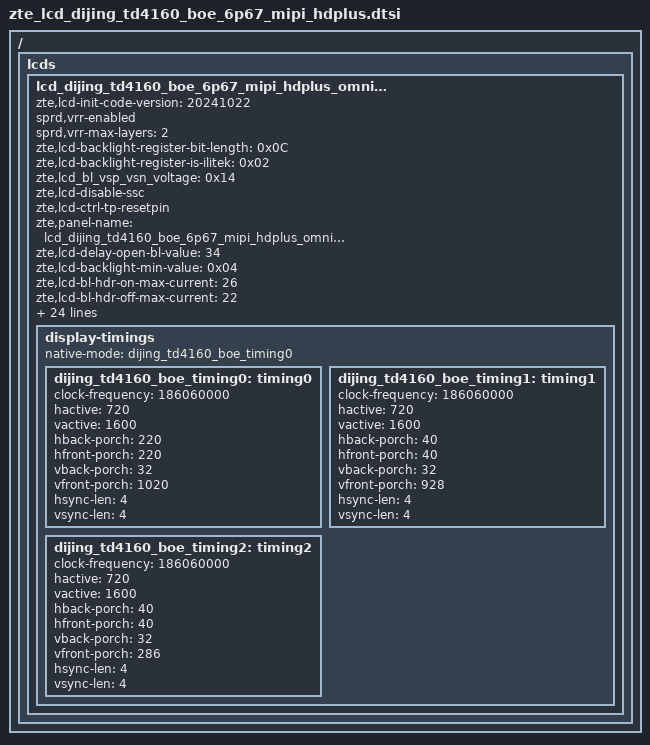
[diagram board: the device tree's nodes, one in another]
/ {
	fragment {
		target-path = "/";
		__overlay__ {
			lcds {
				lcd_dijing_td4160_boe_6p67_mipi_hdplus_omnivision: lcd_dijing_td4160_boe_6p67_mipi_hdplus_omnivision {
					zte,lcd-init-code-version = "20241022";
					sprd,vrr-enabled;
					sprd,vrr-max-layers = <2>;
					zte,lcd-backlight-register-bit-length = <0x0C>;
					zte,lcd-backlight-register-is-ilitek = <0x02>;/*51h=0xff0f*/
					zte,lcd_bl_vsp_vsn_voltage = <0x14>;
					zte,lcd-disable-ssc;
					zte,lcd-ctrl-tp-resetpin;
					zte,panel-name = "lcd_dijing_td4160_boe_6p67_mipi_hdplus_omnivision";
					zte,lcd-delay-open-bl-value = <34>;
					zte,lcd-backlight-min-value = <0x04>;
					zte,lcd-bl-hdr-on-max-current = <26>;
					zte,lcd-bl-hdr-off-max-current = <22>;

					sprd,dsi-work-mode = <1>;
					sprd,dsi-lane-number = <4>;
					sprd,dsi-color-format = "rgb888";

					sprd,dpi-clk-div = <6>;
					sprd,video-lp-cmd-enable = <1>;
					sprd,hporch-lp-disable = <1>;

					sprd,phy-bit-clock = <1116360>;
					sprd,phy-escape-clock = <20000>;/* kHz */

					sprd,width-mm = <6955>;
					sprd,height-mm = <15456>;

					sprd,esd-check-enable = <1>;/* 0:close , 1:open */
					sprd,esd-check-mode = <1>;/* 0:REG ,1:TE  */
					sprd,esd-check-period = <2000>;
					sprd,esd-check-register = <0x0A>;
					sprd,esd-check-value = <0x9C>;

					sprd,dphy-taget-val = <5>;

					sprd,reset-on-sequence = <1 5>, <0 15>, <1 50>;
					sprd,reset-off-sequence = <0 20>;

		sprd,initial-command = [
29 00 00 02 B0 00
29 00 00 07 B6 30 6b 00 86 c3 03
29 00 00 05 B7 31 00 00 00
29 00 00 07 B8 00 78 64 10 64 b4
29 00 00 07 B9 00 78 64 10 64 b4
29 00 00 07 BA 00 78 64 10 64 b4
29 00 00 04 BB 00 b4 a0
29 00 00 04 BC 00 b4 a0
29 00 00 04 BD 00 b4 a0
29 00 00 0E BE 07 00 00 00 00 00 00 00 00 00 00 00 00
29 00 00 19 C0 00 45 24 06 40 00 0a 06 94 00 70 00 00 00 00 00 00 00 00 00 00 00 00 00
29 00 00 28 C1 30 81 50 fa 01 00 00 10 00 00 00 00 40 0f 00 00 00 00 00 00 00 00 00 00 00 00 00 00 00 00 00 00 00 00 00 00 00 00 00
29 00 00 F5 C2 03 90 39 12 09 10 13 12 00 03 90 39 12 09 10 0f 11 00 00 00 00 00 00 00 00 00 00 00 00 00 00 00 00 00 00 00 00 00 00 00 00 00 03 90 32 10 10 08 05 c9 00 f0 01 00 00 00 08 00 00 00 00 11 00 f0 01 00 00 00 00 00 00 00 00 00 00 00 00 00 00 00 00 00 00 00 00 00 00 00 00 00 00 00 00 11 00 00 00 00 00 00 00 00 00 00 00 00 00 00 00 00 00 00 00 00 00 00 00 00 00 00 00 00 00 00 00 11 00 00 00 00 00 00 00 00 00 00 00 00 00 00 00 00 00 00 00 00 00 00 00 00 00 00 00 00 00 00 00 11 00 00 00 00 00 00 00 00 00 00 00 00 00 00 00 00 00 00 00 00 00 00 00 00 00 00 00 00 00 00 00 00 00 00 00 00 00 00 00 10 00 00 00 00 00 00 00 00 00 00 00 00 00 00 00 02 00 00 00 00 00 00 00 00 00 00 02 00 00 00 00 00 00 00 00 00 00 00 00 00 00 00 00 00 00 00
29 00 00 6A C3 03 90 39 c1 01 40 09 00 00 00 20 00 00 00 00 01 00 00 00 00 00 00 23 00 00 60 48 c1 01 30 09 00 00 00 22 00 03 90 39 c1 01 40 09 00 00 00 20 00 00 00 00 08 00 00 00 00 00 00 00 00 00 00 00 00 00 00 00 00 00 00 00 00 00 00 00 00 00 00 00 00 00 00 00 00 00 00 00 00 00 00 00 00 00 00 00 00 00 00 00 00 00 00 00 00 00
29 00 00 55 C4 00 00 67 61 03 07 13 15 17 19 1B 1D 1F 21 60 00 00 00 00 00 00 00 00 00 00 00 00 00 00 00 00 60 22 20 1E 1C 1A 18 16 14 08 04 61 67 00 00 00 00 00 00 00 E0 1F 00 80 7F 00 00 00 00 00 00 00 00 00 00 00 00 00 00 00 00 00 55 55 55 55 55 55 55 55 55 55 55
29 00 00 06 C5 08 00 00 00 00
29 00 00 4D C6 00 00 00 00 01 22 04 22 01 00 46 00 00 00 01 00 46 00 01 05 01 0b 01 35 ff 0f 06 c5 02 c0 0f 00 00 00 00 00 00 00 00 00 00 00 00 00 00 00 00 00 00 00 00 00 00 20 20 00 00 00 c0 11 00 00 00 10 10 00 00 00 01 00 50 00 33 03 00 00
29 00 00 1F CB 02 d0 01 80 00 00 00 00 00 00 00 00 00 00 00 00 00 00 00 00 00 00 40 70 00 00 00 00 00 ff
29 00 00 19 CE 5d 40 43 49 55 62 71 82 94 a8 b9 cb db e9 f5 fc ff 04 00 04 04 00 00 00
29 00 00 02 CF 00
29 00 00 15 D0 c1 46 81 66 09 90 00 d5 92 9f 11 46 06 7e 09 08 dc 1b f0 06
29 00 00 26 D1 d4 d4 1b 33 33 17 07 bb 55 55 55 55 00 3b 77 07 3b 30 06 72 33 13 00 d7 0c 55 02 00 18 70 18 77 11 11 11 20 20
29 00 00 04 D2 00 00 00
29 00 00 9A D3 00 00 00 00 00 00 00 00 00 ff f7 ff ff f7 ff ff f7 ff ff f7 ff ff f7 ff ff f7 ff ff f7 ff ff f7 ff ff f7 ff ff f7 ff ff f7 ff ff f7 ff ff f7 ff ff f7 ff ff f7 ff ff f7 ff ff f7 ff ff f7 ff ff f7 ff ff f7 ff ff f7 ff ff f7 ff ff f7 ff ff f7 ff ff f7 ff ff f7 ff ff f7 ff ff f7 ff ff f7 ff ff f7 ff ff f7 ff ff f7 ff ff f7 ff ff f7 ff ff f7 ff ff f7 ff ff f7 ff ff f7 ff ff f7 ff ff f7 ff ff f7 ff ff f7 ff ff f7 ff ff f7 ff ff f7 ff ff f7 ff ff f7 ff ff f7 ff
29 00 00 18 D4 00 00 00 00 00 00 00 00 00 20 00 00 00 00 20 00 00 00 00 00 00 00 00
29 00 00 2F D7 01 00 12 12 00 45 00 18 00 45 00 18 03 83 80 85 85 85 87 84 45 86 87 80 88 86 89 83 83 87 84 88 8a 0c 0b 0a 0a 0a 07 07 06 06 00 08 0a 0a
29 00 00 17 D8 40 99 26 ed 16 6c 16 6c 16 6c 00 14 00 14 00 14 01 0c 00 00 01 00
29 00 00 29 D9 00 02 7f 00 00 00 00 00 00 00 00 00 00 00 00 c0 00 00 00 00 00 00 00 00 00 00 00 00 00 00 00 00 00 00 00 00 00 00 00 00
29 00 00 05 DD 30 06 23 65
29 00 00 0F DE 00 00 00 0f ff 00 00 00 00 10 00 00 00 00
29 00 00 09 E6 00 00 00 00 00 00 00 00
29 00 00 24 EA 02 07 07 04 80 10 01 00 00 00 00 03 23 00 07 00 ed 00 ed 00 ed 01 28 01 28 00 47 00 47 00 47 01 0f 01 00
29 00 00 09 EB 09 90 99 00 01 00 00 00
29 00 00 18 EC 02 d0 01 70 73 10 01 00 00 00 00 02 2a 00 00 00 00 00 00 00 00 00 00
29 00 00 22 ED 01 02 00 00 00 00 00 00 66 f7 07 00 00 00 00 00 00 00 00 00 00 00 02 b0 00 00 00 00 00 00 40 10 00
29 00 00 7A EE 05 40 05 00 c0 1f 00 c0 1f 00 00 03 00 00 03 00 c0 1f 00 00 00 00 00 00 03 00 00 00 00 00 00 03 00 00 00 00 00 00 03 00 00 00 00 00 00 03 40 c0 0f 00 00 00 00 00 c0 1f 00 00 00 00 00 c0 1f 00 00 00 00 05 d5 1f 00 00 00 00 00 00 03 00 00 03 00 00 03 00 00 03 00 00 03 00 00 03 00 00 03 00 00 10 00 00 00 00 00 00 00 00 00 00 00 00 00 00 00 00 00 00 00 00 00 00 02
29 00 00 02 B0 03
29 00 00 02 B0 00
29 00 00 02 D6 00
29 00 00 02 B0 03
29 00 00 02 51 00
29 00 00 02 53 0C
29 00 00 02 55 00
39 00 00 02 35 00
29 00 00 02 B0 03
05 78 00 01 11
05 14 00 01 29
		];

					sprd,sleep-in-command = [
						05 14 00 01 28
						05 78 00 01 10
						29 00 00 02 00 00
						29 14 00 05 F7 5A A5 95 27
						];
					sprd,sleep-out-command = [
						05 78 00 01 11
						05 64 00 01 29
						];

					display-timings {
						native-mode = <&dijing_td4160_boe_timing0>;
						dijing_td4160_boe_timing0: timing0 {/*60hz*/
							clock-frequency = <186060000>;
							hactive = <720>;
 							vactive = <1600>;
							hback-porch = <220>;
							hfront-porch = <220>;
 							vback-porch = <32>;
							vfront-porch = <1020>;
							hsync-len = <4>;
 							vsync-len = <4>;
 
 						};
						dijing_td4160_boe_timing1: timing1 {/*90hz*/
							clock-frequency = <186060000>;
							hactive = <720>;
							vactive = <1600>;
							hback-porch = <40>;
							hfront-porch = <40>;
 							vback-porch = <32>;
							vfront-porch = <928>;
							hsync-len = <4>;
 							vsync-len = <4>;
						};

						 dijing_td4160_boe_timing2: timing2 {/*120hz*/
							clock-frequency = <186060000>;
 							hactive = <720>;
 							vactive = <1600>;
							hback-porch = <40>;
							hfront-porch = <40>;
 							vback-porch = <32>;
							vfront-porch = <286>;
							hsync-len = <4>;
 							vsync-len = <4>;
 
						};
					};
				};
			};
		};
	};
};
